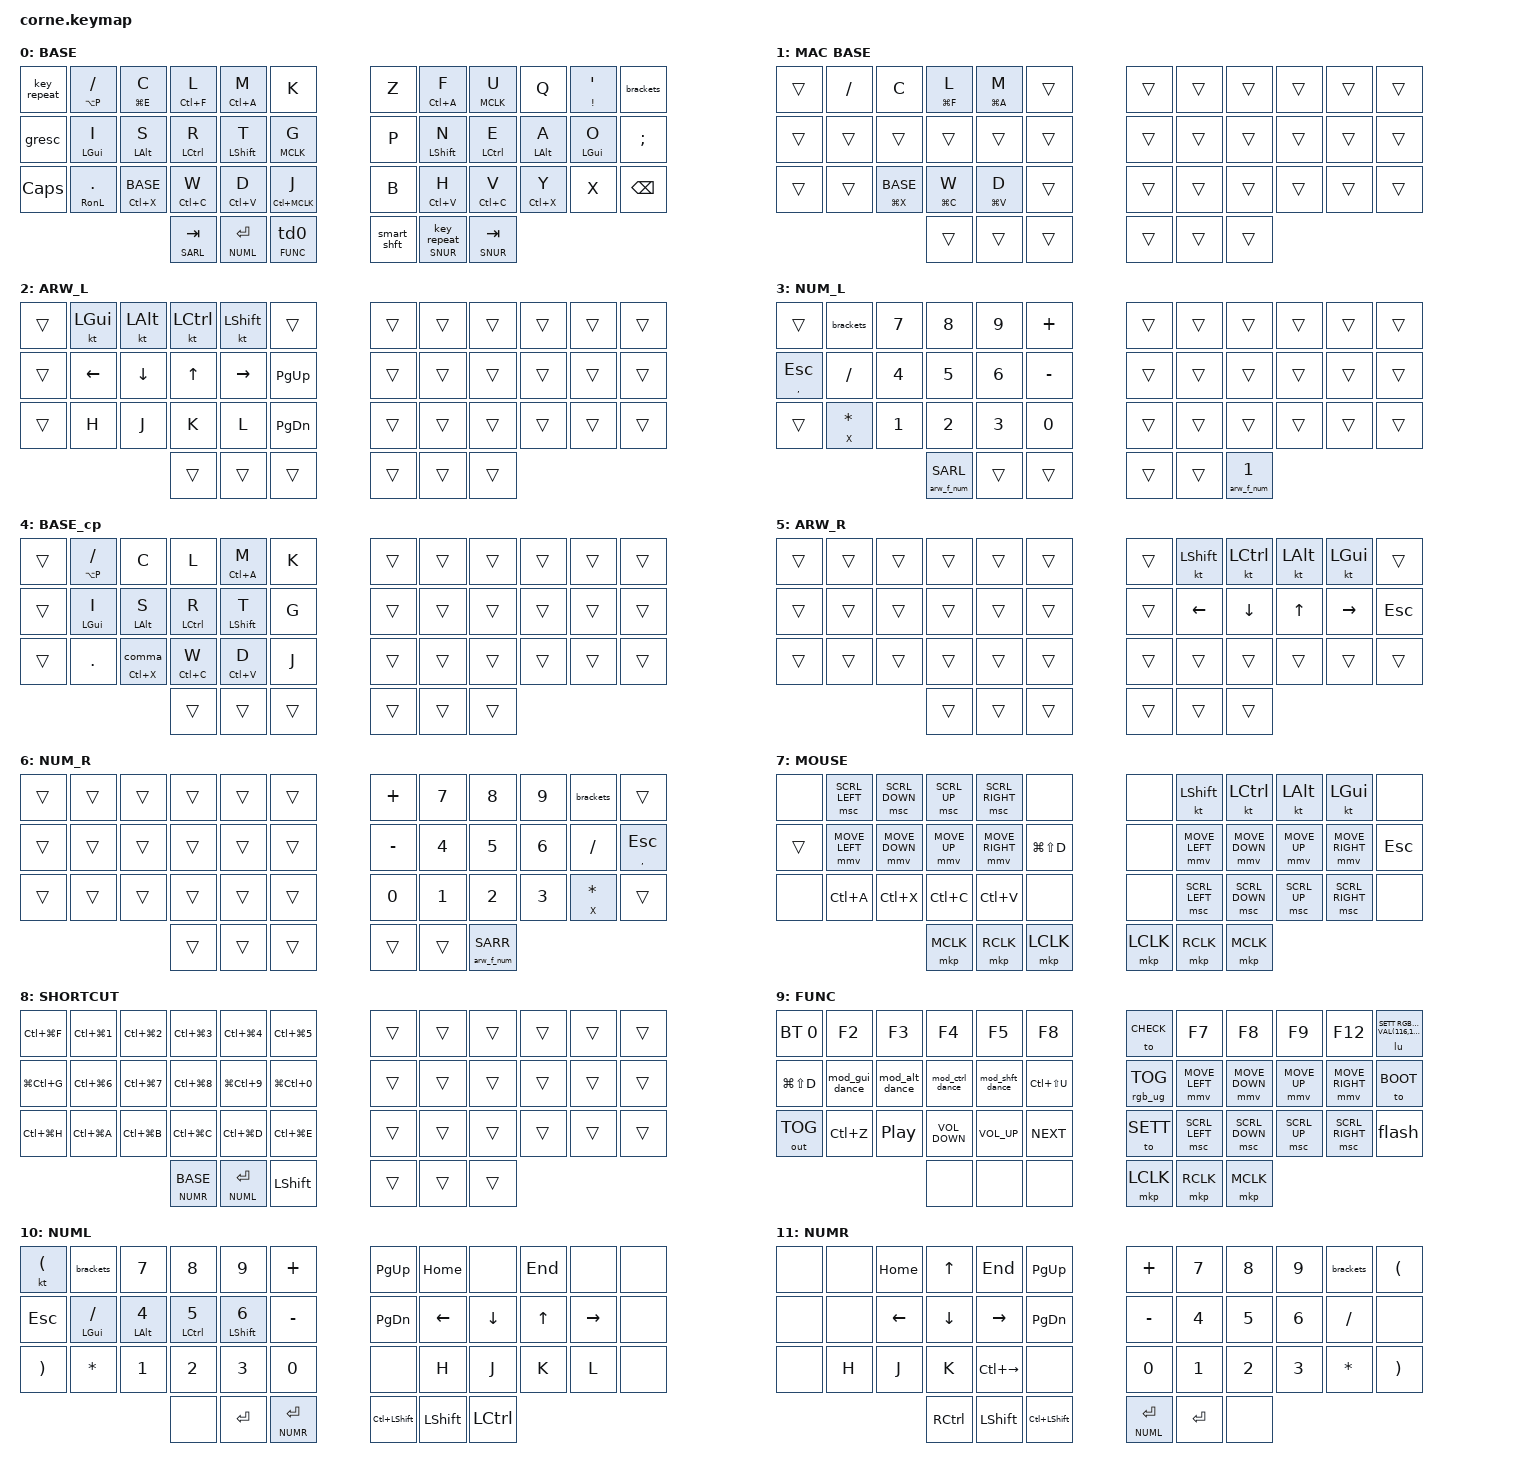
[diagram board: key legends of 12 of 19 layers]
/*
 * Copyright (c) 2020 The ZMK Contributors
 *
 * SPDX-License-Identifier: MIT
 */

#include <behaviors/num_word.dtsi>
#include "zmk-helpers/helper.h"
#include <dt-bindings/zmk/mouse.h>
#include <behaviors.dtsi>
#include <dt-bindings/zmk/bt.h>
#include <dt-bindings/zmk/ext_power.h>
#include <dt-bindings/zmk/keys.h>
#include <dt-bindings/zmk/outputs.h>
//#include <dt-bindings/zmk/pointing.h>
#include <dt-bindings/zmk/rgb.h>

#define BASE 0
#define BMAC 1
#define SARL 2
#define SNUL 3
#define BSCP 4
#define SARR 5
#define SNUR 6
#define MOUS 7
#define SHCT 8
#define FUNC 9
#define NUML 10
#define NUMR 11
#define SETT 12
#define SYMB 13
#define NAV 14
#define CHECK 15
#define BOOT 16
#define TYPI 17
#define RonL 18

//&led_strip { chain-length = <27>; };

&sl { release-after-ms = <2000>; };

&mt {
    flavor = "balanced";
    quick-tap-ms = <175>;
    require-prior-idle-ms = <150>;
};

&sk { quick-release; };

&mmv {
    acceleration-exponent = <1>;
    time-to-max-speed-ms = <1500>;
    delay-ms = <0>;
};

&msc {
    acceleration-exponent = <1>;
    time-to-max-speed-ms = <500>;
    delay-ms = <0>;
};

/ {
    combos {
        compatible = "zmk,combos";

        combo_num_pad_right_layer {
            bindings = <&tog NUML>;
            key-positions = <2 3 4>;
            require-prior-idle-ms = <125>;
        };

        combo_num_pad_left_layer {
            bindings = <&tog NUMR>;
            key-positions = <19 20 21>;
            require-prior-idle-ms = <125>;
        };

        combo_settings_layer {
            bindings = <&tog SETT>;
            key-positions = <1 2 3 4>;
            require-prior-idle-ms = <125>;
        };

        combo_symbols_layer {
            bindings = <&sl SYMB>;
            key-positions = <31 32 33>;
            require-prior-idle-ms = <125>;
        };

        combo_shortcuts_layer {
            bindings = <&tog SHCT>;
            key-positions = <28 26>;
            require-prior-idle-ms = <125>;
        };

        combo_num_pad_right_layer_Lhand {
            bindings = <&tog NUMR>;
            key-positions = <14 3 16>;
            require-prior-idle-ms = <125>;
        };

        combo_num_pad_left_layer_Rhand {
            bindings = <&tog NUML>;
            key-positions = <19 8 21>;
            require-prior-idle-ms = <125>;
        };

        combo_default_layer {
            bindings = <&to 0>;
            key-positions = <38 39>;
            require-prior-idle-ms = <125>;
        };

        combo_symbols_layer_sticky {
            bindings = <&sl SYMB>;
            key-positions = <31 33>;
            require-prior-idle-ms = <125>;
        };

        combo_dot_left {
            bindings = <&kp PERIOD>;
            key-positions = <27 28>;
            layers = <NUML SNUL>;
            require-prior-idle-ms = <125>;
            timeout-ms = <20>;
        };

        combo_dot_right {
            bindings = <&kp PERIOD>;
            key-positions = <31 32>;
            layers = <NUMR SNUR>;
            require-prior-idle-ms = <125>;
            timeout-ms = <20>;
        };

        combo_delete_right {
            bindings = <&kp DELETE>;
            key-positions = <20 21>;
            layers = <BASE BMAC SNUL SARR SARL>;
            require-prior-idle-ms = <125>;
            timeout-ms = <20>;
        };

        combo_backspace_right {
            bindings = <&kp BACKSPACE>;
            key-positions = <19 20>;
            layers = <BASE BMAC SNUL SARR SARL>;
            timeout-ms = <20>;
        };

        combo_delete_left {
            bindings = <&kp DELETE>;
            key-positions = <15 16>;
            layers = <BASE BMAC SNUR SHCT SARL SARR>;
            require-prior-idle-ms = <125>;
            timeout-ms = <20>;
        };

        combo_backspace_left {
            bindings = <&kp BACKSPACE>;
            key-positions = <14 15>;
            layers = <BASE BMAC SNUL SNUR NUML SARL SARR>;
            require-prior-idle-ms = <125>;
            timeout-ms = <20>;
        };

        combo_equal_left {
            bindings = <&kp EQUAL>;
            key-positions = <15 16>;
            layers = <NUML SNUL>;
            require-prior-idle-ms = <125>;
            timeout-ms = <20>;
        };

        combo_equal_right {
            bindings = <&kp EQUAL>;
            key-positions = <19 20>;
            layers = <NUMR SNUR>;
            require-prior-idle-ms = <125>;
            timeout-ms = <20>;
        };

        combo_navigation_layer {
            bindings = <&sl NAV>;
            key-positions = <14 16>;
            require-prior-idle-ms = <125>;
        };

        combo_left_arrow_Lhand {
            bindings = <&kp LEFT>;
            key-positions = <26 27>;
            layers = <BASE>;
            require-prior-idle-ms = <125>;
            timeout-ms = <20>;
        };

        combo_right_arrow_Lhand {
            bindings = <&kp RIGHT>;
            key-positions = <27 28>;
            layers = <BASE>;
            require-prior-idle-ms = <125>;
            timeout-ms = <20>;
        };

        combo_up_arrow_Lhand {
            bindings = <&kp UP>;
            key-positions = <3 4>;
            layers = <BASE>;
            require-prior-idle-ms = <125>;
            timeout-ms = <20>;
        };

        combo_down_arrow_Lhand {
            bindings = <&kp DOWN>;
            key-positions = <3 2>;
            layers = <BASE>;
            require-prior-idle-ms = <125>;
            timeout-ms = <20>;
        };

        combo_left_arrow_Rhand {
            bindings = <&kp LEFT>;
            key-positions = <32 31>;
            layers = <BASE>;
            require-prior-idle-ms = <125>;
            timeout-ms = <20>;
        };

        combo_right_arrow_Rhand {
            bindings = <&kp RIGHT>;
            key-positions = <32 33>;
            layers = <BASE>;
            require-prior-idle-ms = <125>;
            timeout-ms = <20>;
        };

        combo_up_arrow_Rhand {
            bindings = <&kp UP>;
            key-positions = <7 8>;
            layers = <BASE>;
            require-prior-idle-ms = <125>;
            timeout-ms = <20>;
        };

        combo_down_arrow_Rhand {
            bindings = <&kp DOWN>;
            key-positions = <8 9>;
            layers = <BASE>;
            require-prior-idle-ms = <125>;
            timeout-ms = <20>;
        };

        combo_esc_shortcuts {
            bindings = <&kp ESCAPE>;
            key-positions = <14 15>;
            layers = <SHCT>;
            require-prior-idle-ms = <125>;
        };

        to_0_L {
            bindings = <&to BASE>;
            key-positions = <38 15>;
            require-prior-idle-ms = <125>;
        };

        to_0_R {
            bindings = <&to BASE>;
            key-positions = <39 20>;
            require-prior-idle-ms = <125>;
        };

        combo_backspace_right_num {
            bindings = <&kp BACKSPACE>;
            key-positions = <21 8>;
            require-prior-idle-ms = <125>;
            layers = <SNUR>;
        };

        to_mouse {
            bindings = <&to MOUS>;
            key-positions = <16 38>;
        };

        MAC_layer {
            bindings = <&tog 1>;
            key-positions = <38 4>;
            require-prior-idle-ms = <125>;
        };

        typing_layer {
            bindings = <&to 17>;
            key-positions = <36 41>;
        };
    };

    behaviors {
        ht0: mo_to {
            compatible = "zmk,behavior-hold-tap";
            label = "MOMENTARY LAYER_TO LAYER";
            bindings = <&mo>, <&to>;

            #binding-cells = <2>;
            tapping-term-ms = <200>;
        };

        ht1: mo_td0 {
            compatible = "zmk,behavior-hold-tap";
            label = "MO_TD0";
            bindings = <&mo>, <&td0>;

            #binding-cells = <2>;
            tapping-term-ms = <200>;
            flavor = "tap-preferred";
        };

        ht2: mo_keyrepeat {
            compatible = "zmk,behavior-hold-tap";
            label = "mo_KEYREPEAT";
            bindings = <&mo>, <&key_repeat>;

            #binding-cells = <2>;
            tapping-term-ms = <200>;
        };

        ht3: mo_td2 {
            compatible = "zmk,behavior-hold-tap";
            label = "MO_TD2";
            bindings = <&mo>, <&td2>;

            #binding-cells = <2>;
            tapping-term-ms = <200>;
            flavor = "tap-preferred";
        };

        ht4: hold_comma {
            compatible = "zmk,behavior-hold-tap";
            label = "HOLD_COMMA+SPACE";
            #binding-cells = <2>;
            tapping-term-ms = <200>;
            flavor = "tap-preferred";
            bindings = <&kp>, <&comma>;
        };

        ht5: mouse_kp {
            compatible = "zmk,behavior-hold-tap";
            label = "Mouse_kp";
            bindings = <&mkp>, <&kp>;

            #binding-cells = <2>;
            tapping-term-ms = <200>;
            flavor = "tap-preferred";
        };

        td0: space_dot {
            compatible = "zmk,behavior-tap-dance";
            label = "SPACE_DOT";
            #binding-cells = <0>;
            bindings = <&kp SPACE>, <&dt PERIOD SPACE>;

            tapping-term-ms = <250>;
        };

        td1: stick_toggle_alt {
            compatible = "zmk,behavior-tap-dance";
            label = "STICK_TOGGLE_ALT";
            #binding-cells = <0>;
            bindings = <&sk LALT>, <&kt LALT>;
        };

        td2: repeat_enter {
            compatible = "zmk,behavior-tap-dance";
            label = "REPEAT_ENTER";
            #binding-cells = <0>;
            bindings = <&key_repeat>, <&kp ENTER>;
        };

        smart_shft: smart_shft {
            compatible = "zmk,behavior-mod-morph";
            #binding-cells = <0>;
            bindings = <&sk LSHFT>, <&caps_word>;

            mods = <(MOD_LSFT)>;
        };

        num_word: num_word {
            compatible = "zmk,behavior-auto-layer";
            #binding-cells = <1>;
            continue-list = <BACKSPACE DELETE DOT COMMA PLUS MINUS STAR FSLH EQUAL LEFT_PARENTHESIS RIGHT_PARENTHESIS LEFT X COMMA>;
            ignore-numbers;
            label = "Smart Numpad Layer";
        };

        num_arrow: num_arrow {
            compatible = "zmk,behavior-auto-layer";
            #binding-cells = <1>;
            continue-list = <UP DOWN RIGHT LEFT LGUI LALT LCTRL LSHFT BACKSPACE DELETE>;
            ignore-numbers;
            label = "Smart arrow layer";
        };

        smart_num: smart_num {
            compatible = "zmk,behavior-hold-tap";
            label = "Smart Numpad";
            bindings = <&num_word>, <&kp>;

            #binding-cells = <2>;
            tapping-term-ms = <150>;
            flavor = "balanced";
        };

        smart_num_rpt: smart_num_rpt {
            compatible = "zmk,behavior-hold-tap";
            label = "Smart Numpad+Rpt";
            bindings = <&num_word>, <&key_repeat>;

            #binding-cells = <2>;
            tapping-term-ms = <150>;
            flavor = "balanced";
        };

        smart_arrow: smart_arrow {
            compatible = "zmk,behavior-hold-tap";
            label = "Smart Arrow Pad";
            bindings = <&num_arrow>, <&kp>;

            #binding-cells = <2>;
            tapping-term-ms = <150>;
            flavor = "balanced";
        };

        mod_gui_dance: mod_gui_dance {
            compatible = "zmk,behavior-tap-dance";
            label = "MOD_GUI_DANCE";
            #binding-cells = <0>;
            bindings = <&sk LGUI>, <&kt LGUI>;

            tapping-term-ms = <300>;
        };

        mod_alt_dance: mod_alt_dance {
            compatible = "zmk,behavior-tap-dance";
            label = "MOD_ALT_DANCE";
            #binding-cells = <0>;
            bindings = <&sk LALT>, <&kt LALT>;

            tapping-term-ms = <300>;
        };

        mod_ctrl_dance: mod_ctrl_dance {
            compatible = "zmk,behavior-tap-dance";
            label = "MOD_CTRL_DANCE";
            #binding-cells = <0>;
            bindings = <&sk LCTRL>, <&kt LCTRL>;

            tapping-term-ms = <300>;
        };

        mod_shft_dance: mod_shft_dance {
            compatible = "zmk,behavior-tap-dance";
            label = "MOD_SHFT_DANCE";
            #binding-cells = <0>;
            bindings = <&sk LSHFT>, <&kt LSHFT>;

            tapping-term-ms = <300>;
        };

        smrt_num_arrw: smart_num_arrw {
            compatible = "zmk,behavior-tap-dance";
            label = "Smart Numpad and Arrowpad";
            #binding-cells = <0>;
            bindings = <&num_word SARR>, <&num_arrow SNUR>;

            tapping-term-ms = <300>;
        };

        numpad_rpt: numpad_rpt {
            compatible = "zmk,behavior-hold-tap";
            label = "NUMPAD_RPT";
            bindings = <&mo>, <&key_repeat>;

            #binding-cells = <2>;
            tapping-term-ms = <150>;
            flavor = "balanced";
        };
    };

    macros {
        dt: dt {
            compatible = "zmk,behavior-macro-two-param";
            #binding-cells = <2>;
            bindings = <&macro_param_1to1 &kp MACRO_PLACEHOLDER &macro_param_2to1 &kp MACRO_PLACEHOLDER>;
            label = "DOUBLE_TAP";
        };

        lu: lu {
            compatible = "zmk,behavior-macro-two-param";
            wait-ms = <0>;
            tap-ms = <0>;
            bindings =
                <&macro_press>,
                <&macro_param_1to1 &mo MACRO_PLACEHOLDER>,
                <&macro_tap>,
                <&rgb_ug RGB_ON &macro_param_2to2 &rgb_ug RGB_COLOR_HSB_CMD MACRO_PLACEHOLDER>,
                <&macro_pause_for_release>,
                <&macro_release>,
                <&macro_param_1to1 &mo MACRO_PLACEHOLDER>,
                <&macro_tap>,
                <&rgb_ug RGB_OFF>;

            label = "LAYER_UNDERGLOW";
            #binding-cells = <2>;
        };

        lu_white: lu_white {
            compatible = "zmk,behavior-macro-one-param";
            wait-ms = <0>;
            tap-ms = <0>;
            bindings =
                <&macro_press>,
                <&macro_param_1to1 &mo MACRO_PLACEHOLDER &rgb_ug RGB_ON &rgb_ug RGB_COLOR_HSB(0,100,52)>,
                <&macro_tap>,
                <&macro_pause_for_release>,
                <&macro_release>,
                <&macro_param_1to1 &mo MACRO_PLACEHOLDER>,
                <&macro_tap>,
                <&rgb_ug RGB_OFF>;

            label = "LAYER_UNDERGLOW";
            #binding-cells = <1>;
        };

        comma: comma {
            compatible = "zmk,behavior-macro";
            #binding-cells = <0>;
            bindings = <&kp COMMA &kp SPACE>;
            label = "COMMA";
        };

        flash: dongle_bootloader_macro {
            compatible = "zmk,behavior-macro";
            #binding-cells = <0>;
            bindings = <&to BOOT &bootloader>;
            label = "Dongle Bootloader";
        };

        brackets: brackets {
            compatible = "zmk,behavior-macro";
            #binding-cells = <0>;
            bindings = <&kp LEFT_PARENTHESIS &kp RIGHT_PARENTHESIS &kp LEFT>;
            label = "BRACKETS";
        };

        arw_f_num: arw_f_num {
            compatible = "zmk,behavior-macro-one-param";
            #binding-cells = <1>;
            bindings = <&to BASE &macro_param_1to1 &num_arrow MACRO_PLACEHOLDER>;
            label = "Smart Arrow from Numpad";
        };

        n_a: n_a {
            compatible = "zmk,behavior-macro";
            #binding-cells = <0>;
            bindings = <&kp N &kp SLASH &kp A>;
            label = "N_A";
        };

        mouse_jump: mouse_jump {
            compatible = "zmk,behavior-macro-one-param";
            #binding-cells = <1>;
            bindings = <&kp LG(LS(D)) &macro_param_1to1 &kp MACRO_PLACEHOLDER>;
            label = "MOUSE_JUMP";
        };
    };

    keymap {
        compatible = "zmk,keymap";

        WB_LAYER {
            // -----------------------------------------------------------------------------------------
            // | TAB |  /  |  C  |  L   |  M   |  K   |   |  Z   |  F  |  U  |  Q  |  '  |  [  |
            // | ESC |  I  |  S  |  R   |  T   |  G   |   |  P   |  N  |  E  |  A  |  O  |  ;  |
            // | DEL |  .  |  ,  |  W   |  D   |  J   |   |  B   |  H  |  V  |  Y  |  X  |  ]  |
            //                   | SHFT | BKSP | CTRL |   | CTRL | ENT | GUI |

            label = "BASE";
            bindings = <
&key_repeat  &mt LA(P) SLASH  &mt LG(E) C      &mt LC(F) L            &mt LC(A) M     &kp K             &kp Z        &mt LC(A) F         &ht5 MCLK U          &kp Q        &mt EXCLAMATION SQT  &brackets
&gresc       &mt LGUI I       &mt LALT S       &mt LCTRL R            &mt LSHFT T     &ht5 MCLK G       &kp P        &mt LSHFT N         &mt LCTRL E          &mt LALT A   &mt LGUI O           &kp SEMI
&kp CAPS     &lt RonL DOT     &ht4 LC(X) BASE  &mt LC(C) W            &mt LC(V) D     &mt LC(MCLK) J    &kp B        &mt LC(V) H         &mt LC(C) V          &mt LC(X) Y  &kp X                &kp BACKSPACE
                                               &smart_arrow SARL TAB  &lt NUML ENTER  &ht1 FUNC 0       &smart_shft  &numpad_rpt SNUR 0  &smart_num SNUR TAB
            >;
        };

        MAC_layer {
            label = "MAC BASE";
            bindings = <
&trans  &kp SLASH  &kp C            &mt LG(F) L  &mt LG(A) M  &trans    &trans  &trans  &trans  &trans  &trans  &trans
&trans  &trans     &trans           &trans       &trans       &trans    &trans  &trans  &trans  &trans  &trans  &trans
&trans  &trans     &ht4 LG(X) BASE  &mt LG(C) W  &mt LG(V) D  &trans    &trans  &trans  &trans  &trans  &trans  &trans
                                    &trans       &trans       &trans    &trans  &trans  &trans
            >;
        };

        SMART_ARROW_L {
            label = "ARW_L";
            bindings = <
&trans  &kt LGUI  &kt LALT  &kt LCTRL  &kt LSHFT  &trans           &trans  &trans  &trans  &trans  &trans  &trans
&trans  &kp LEFT  &kp DOWN  &kp UP     &kp RIGHT  &kp PAGE_UP      &trans  &trans  &trans  &trans  &trans  &trans
&trans  &kp H     &kp J     &kp K      &kp L      &kp PAGE_DOWN    &trans  &trans  &trans  &trans  &trans  &trans
                            &trans     &trans     &trans           &trans  &trans  &trans
            >;
        };

        SMART_NUMPAD_L {
            label = "NUM_L";
            bindings = <
&trans            &brackets       &kp N7  &kp N8           &kp N9  &kp PLUS     &trans  &trans  &trans        &trans  &trans  &trans
&mt COMMA ESCAPE  &kp SLASH       &kp N4  &kp N5           &kp N6  &kp MINUS    &trans  &trans  &trans        &trans  &trans  &trans
&trans            &mt X ASTERISK  &kp N1  &kp N2           &kp N3  &kp N0       &trans  &trans  &trans        &trans  &trans  &trans
                                          &arw_f_num SARL  &trans  &trans       &trans  &trans  &arw_f_num 1
            >;
        };

        BASE_COPY {
            label = "BASE_cp";
            bindings = <
&trans  &mt LA(P) SLASH  &kp C         &kp L        &mt LC(A) M  &kp K     &trans  &trans  &trans  &trans  &trans  &trans
&trans  &mt LGUI I       &mt LALT S    &mt LCTRL R  &mt LSHFT T  &kp G     &trans  &trans  &trans  &trans  &trans  &trans
&trans  &kp PERIOD       &ht4 LC(X) 0  &mt LC(C) W  &mt LC(V) D  &kp J     &trans  &trans  &trans  &trans  &trans  &trans
                                       &trans       &trans       &trans    &trans  &trans  &trans
            >;
        };

        SMART_ARROW_R {
            label = "ARW_R";
            bindings = <
&trans  &trans  &trans  &trans  &trans  &trans    &trans  &kt LSHIFT  &kt LCTRL  &kt LALT  &kt LGUI   &trans
&trans  &trans  &trans  &trans  &trans  &trans    &trans  &kp LEFT    &kp DOWN   &kp UP    &kp RIGHT  &kp ESCAPE
&trans  &trans  &trans  &trans  &trans  &trans    &trans  &trans      &trans     &trans    &trans     &trans
                        &trans  &trans  &trans    &trans  &trans      &trans
            >;
        };

        SMART_NUMPAD_R {
            label = "NUM_R";
            bindings = <
&trans  &trans  &trans  &trans  &trans  &trans    &kp PLUS   &kp N7  &kp N8           &kp N9  &brackets       &trans
&trans  &trans  &trans  &trans  &trans  &trans    &kp MINUS  &kp N4  &kp N5           &kp N6  &kp SLASH       &mt COMMA ESCAPE
&trans  &trans  &trans  &trans  &trans  &trans    &kp N0     &kp N1  &kp N2           &kp N3  &mt X ASTERISK  &trans
                        &trans  &trans  &trans    &trans     &trans  &arw_f_num SARR
            >;
        };

        MOUSE {
            label = "MOUSE";
            bindings = <
&none   &msc SCRL_LEFT  &msc SCRL_DOWN  &msc SCRL_UP  &msc SCRL_RIGHT  &none            &none      &kt LSHIFT      &kt LCTRL       &kt LALT      &kt LGUI         &none
&trans  &mmv MOVE_LEFT  &mmv MOVE_DOWN  &mmv MOVE_UP  &mmv MOVE_RIGHT  &kp LG(LS(D))    &none      &mmv MOVE_LEFT  &mmv MOVE_DOWN  &mmv MOVE_UP  &mmv MOVE_RIGHT  &kp ESCAPE
&none   &kp LC(A)       &kp LC(X)       &kp LC(C)     &kp LC(V)        &none            &none      &msc SCRL_LEFT  &msc SCRL_DOWN  &msc SCRL_UP  &msc SCRL_RIGHT  &none
                                        &mkp MCLK     &mkp RCLK        &mkp LCLK        &mkp LCLK  &mkp RCLK       &mkp MCLK
            >;
        };

        SHORTCUT_LAYER_WIN {
            bindings = <
&kp LC(LG(F))  &kp LC(LG(N1))        &kp LC(LG(N2))  &kp LC(LG(NUMBER_3))  &kp LC(LG(NUMBER_4))  &kp LC(LG(N5))    &trans  &trans  &trans  &trans  &trans  &trans
&kp LG(LC(G))  &kp LC(LG(NUMBER_6))  &kp LC(LG(N7))  &kp LC(LG(N8))        &kp LG(LC(N9))        &kp LG(LC(N0))    &trans  &trans  &trans  &trans  &trans  &trans
&kp LC(LG(H))  &kp LC(LG(A))         &kp LC(LG(B))   &kp LC(LG(C))         &kp LC(LG(D))         &kp LC(LG(E))     &trans  &trans  &trans  &trans  &trans  &trans
                                                     &ht0 NUMR BASE        &lt NUML ENTER        &kp LSHFT         &trans  &trans  &trans
            >;

            label = "SHORTCUT";
        };

        FUNCTION_KEYS {
            label = "FUNC";
            bindings = <
&bt BT_SEL 0   &kp F2          &kp F3            &kp F4             &kp F5           &kp F8           &to CHECK        &kp F7          &kp F8          &kp F9        &kp F12          &lu SETT RGB_COLOR_HSB_VAL(116,100,79)
&kp LG(LS(D))  &mod_gui_dance  &mod_alt_dance    &mod_ctrl_dance    &mod_shft_dance  &kp LC(LS(U))    &rgb_ug RGB_TOG  &mmv MOVE_LEFT  &mmv MOVE_DOWN  &mmv MOVE_UP  &mmv MOVE_RIGHT  &to BOOT
&out OUT_TOG   &kp LC(Z)       &kp C_PLAY_PAUSE  &kp C_VOLUME_DOWN  &kp C_VOLUME_UP  &kp C_NEXT       &to SETT         &msc SCRL_LEFT  &msc SCRL_DOWN  &msc SCRL_UP  &msc SCRL_RIGHT  &flash
                                                 &none              &none            &none            &mkp LCLK        &mkp RCLK       &mkp MCLK
            >;
        };

        NUM_PAD_LEFT {
            label = "NUML";
            bindings = <
&kt LEFT_PARENTHESIS   &brackets       &kp N7       &kp N8        &kp N9             &kp PLUS          &kp PAGE_UP    &kp HOME   &none      &kp END  &none      &none
&kp ESCAPE             &mt LGUI SLASH  &mt LALT N4  &mt LCTRL N5  &mt LEFT_SHIFT N6  &kp MINUS         &kp PAGE_DOWN  &kp LEFT   &kp DOWN   &kp UP   &kp RIGHT  &none
&kp RIGHT_PARENTHESIS  &kp ASTERISK    &kp N1       &kp N2        &kp N3             &kp N0            &none          &kp H      &kp J      &kp K    &kp L      &none
                                                    &none         &kp ENTER          &lt NUMR ENTER    &kp LC(LSHFT)  &kp LSHFT  &kp LCTRL
            >;
        };

        NUM_PAD_RIGHT {
            label = "NUMR";
            bindings = <
&none  &none  &kp HOME  &kp UP     &kp END        &kp PAGE_UP      &kp PLUS        &kp N7     &kp N8  &kp N9  &brackets     &kp LEFT_PARENTHESIS
&none  &none  &kp LEFT  &kp DOWN   &kp RIGHT      &kp PAGE_DOWN    &kp MINUS       &kp N4     &kp N5  &kp N6  &kp SLASH     &none
&none  &kp H  &kp J     &kp K      &kp LC(RIGHT)  &none            &kp N0          &kp N1     &kp N2  &kp N3  &kp ASTERISK  &kp RIGHT_PARENTHESIS
                        &kp RCTRL  &kp LSHFT      &kp LC(LSHFT)    &lt NUML ENTER  &kp ENTER  &none
            >;
        };

        SETTINGS {
            // -----------------------------------------------------------------------------------------
            // |  TAB |  1  |  2  |  3  |  4  |  5  |   |  6  |  7  |  8  |  9  |  0  | BKSP |
            // | BTCLR| BT1 | BT2 | BT3 | BT4 | BT5 |   | LFT | DWN |  UP | RGT |     |      |
            // | SHFT |     |     |     |     |     |   |     |     |     |     |     |      |
            //                    | GUI |     | SPC |   | ENT |     | ALT |

            label = "SETTINGS";
            bindings = <
&soft_off   &none         &none         &none              &out OUT_TOG      &ext_power EP_TOG    &rgb_ug RGB_SAD  &rgb_ug RGB_SAI                  &rgb_ug RGB_HUD                  &rgb_ug RGB_HUI                    &rgb_ug RGB_COLOR_HSB(0,0,100)     &rgb_ug RGB_COLOR_HSB(0,95,49)
&bt BT_CLR  &bt BT_SEL 0  &bt BT_SEL 1  &bt BT_SEL 2       &bt BT_SEL 3      &bt BT_SEL 4         &rgb_ug RGB_EFF  &rgb_ug RGB_TOG                  &rgb_ug RGB_BRD                  &rgb_ug RGB_BRI                    &none                              &rgb_ug RGB_SPI
&none       &none         &none         &ext_power EP_OFF  &ext_power EP_ON  &none                &rgb_ug RGB_EFR  &rgb_ug RGB_COLOR_HSB(0,100,98)  &rgb_ug RGB_COLOR_HSB(0,100,50)  &rgb_ug RGB_COLOR_HSB(111,100,50)  &rgb_ug RGB_COLOR_HSB(263,100,50)  &rgb_ug RGB_SPD
                                        &none              &none             &to BASE             &to BASE         &none                            &none
            >;
        };

        SYMBOLS {
            // -----------------------------------------------------------------------------------------
            // |  TAB |  !  |  @  |  #  |  $  |  %  |   |  ^  |  &  |  *  |  (  |  )  | BKSP |
            // | CTRL |     |     |     |     |     |   |  -  |  =  |  [  |  ]  |  \  |  `   |
            // | SHFT |     |     |     |     |     |   |  _  |  +  |  {  |  }  | "|" |  ~   |
            //                    | GUI |     | SPC |   | ENT |     | ALT |

            label = "SYMBOLS";
            bindings = <
&kp TAB    &none     &none   &kp TILDE   &kp LC(POUND)  &none        &none      &none     &none      &kp LBRC  &kp RBRC  &kp BSPC
&kp LCTRL  &kp EXCL  &kp AT  &kp DOLLAR  &kp POUND      &kp PRCNT    &kp CARET  &kp AMPS  &kp ASTRK  &kp LPAR  &kp RPAR  &kp GRAVE
&kp LSHFT  &none     &none   &kp EQUAL   &kp MINUS      &kp PLUS     &kp UNDER  &kp BSLH  &kp PIPE   &kp LBKT  &kp RBKT  &kp TILDE
                             &kp LGUI    &none          &kp SPACE    &kp RET    &none     &kp RALT
            >;
        };

        NAVIGATION_LAYER_WIN {
            label = "NAVIGATION";
            bindings = <
&kp RG(F)  &kp RG(NUMBER_1)  &kp RG(NUMBER_2)  &kp RG(NUMBER_3)  &kp RG(NUMBER_4)  &kp RG(N5)    &none  &kp F7  &kp F8  &kp F9  &kp F12  &none
&kp RG(G)  &kp RG(NUMBER_6)  &kp RG(N7)        &kp RG(N8)        &kp RG(N9)        &kp RG(N0)    &none  &kp F4  &kp F5  &kp F6  &kp F11  &none
&kp RG(H)  &kp RG(A)         &kp RG(B)         &kp RG(C)         &kp RG(D)         &kp RG(E)     &none  &kp F1  &kp F2  &kp F3  &kp F10  &none
                                               &none             &none             &none         &none  &none   &none
            >;
        };

        CHECKLIST {
            label = "SER CHECK";
            bindings = <
&none     &none  &none  &none  &none  &none    &none  &none  &none     &none   &none  &none
&none     &none  &none  &none  &none  &none    &none  &kp N  &kp DOWN  &kp UP  &none  &none
&kp CAPS  &none  &none  &none  &none  &none    &none  &n_a   &none     &kp Y   &none  &none
                        &none  &none  &none    &none  &none  &none
            >;
        };

        bootloader_layer {
            label = "flash mode";
            bindings = <
&none  &none  &none  &none        &none   &none    &none  &none   &none        &none  &none  &none
&none  &none  &none  &bootloader  &flash  &none    &none  &flash  &bootloader  &none  &none  &none
&none  &none  &none  &none        &none   &none    &none  &none   &none        &none  &none  &none
                     &none        &none   &none    &none  &none   &none
            >;
        };

        Typing {
            label = "typing";
            bindings = <
&none     &kp SLASH  &kp C            &kp L                  &kp M      &kp K        &kp Z        &kp F               &kp U           &kp Q  &mt EXCLAMATION SQT  &brackets
&gresc    &kp I      &kp S            &kp R                  &kp T      &kp G        &kp P        &kp N               &kp E           &kp A  &kp O                &kp SEMI
&kp CAPS  &kp DOT    &ht4 LC(X) BASE  &kp W                  &kp D      &kp J        &kp B        &kp H               &kp V           &kp Y  &kp X                &kp BACKSPACE
                                      &smart_arrow SARL TAB  &kp ENTER  &kp SPACE    &smart_shft  &numpad_rpt SNUR 0  &num_word SNUR
            >;
        };

        R_on_L_layer {
            label = "R on L";
            bindings = <
&none  &none  &kp Q  &kp U  &kp F  &kp Z    &none  &none  &none  &none  &none  &none
&none  &kp O  &kp A  &kp E  &kp N  &kp P    &none  &none  &none  &none  &none  &none
&none  &none  &kp Y  &kp V  &kp H  &kp B    &none  &none  &none  &none  &none  &none
                     &none  &none  &none    &none  &none  &none
            >;
        };
    };
};
